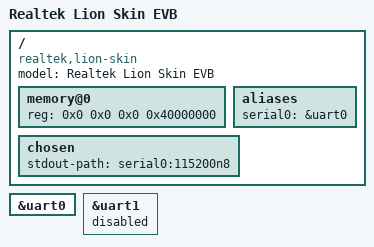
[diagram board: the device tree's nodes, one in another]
// SPDX-License-Identifier: (GPL-2.0-or-later OR BSD-2-Clause)
/*
 * Copyright (c) 2019 Andreas Färber
 */

/dts-v1/;

#include "rtd1395.dtsi"

/ {
	compatible = "realtek,lion-skin", "realtek,rtd1395";
	model = "Realtek Lion Skin EVB";

	memory@0 {
		device_type = "memory";
		reg = <0x0 0x0 0x0 0x40000000>; /* 1 GiB or 2 GiB */
	};

	aliases {
		serial0 = &uart0;
	};

	chosen {
		stdout-path = "serial0:115200n8";
	};
};

/* debug console (J1) */
&uart0 {
	status = "okay";
};

/* M.2 slot (CON1) */
&uart1 {
	status = "disabled";
};
